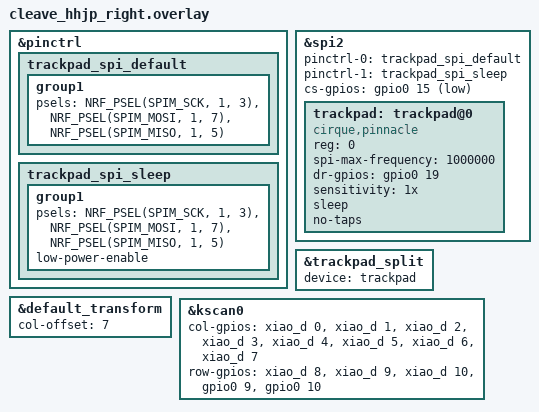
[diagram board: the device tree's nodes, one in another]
/*
 * Copyright (c) 2025
 * SPDX-License-Identifier: MIT
 */

#include "cleave_hhjp.dtsi"
#include "cleave_hhjp_trackpad.dtsi"

&pinctrl {
	trackpad_spi_default: trackpad_spi_default {
		group1 {
			/* Yellow: D17/SCK, blue: D19/SI, green: D18/SO. */
			psels = <NRF_PSEL(SPIM_SCK, 1, 3)>,
				<NRF_PSEL(SPIM_MOSI, 1, 7)>,
				<NRF_PSEL(SPIM_MISO, 1, 5)>;
		};
	};

	trackpad_spi_sleep: trackpad_spi_sleep {
		group1 {
			psels = <NRF_PSEL(SPIM_SCK, 1, 3)>,
				<NRF_PSEL(SPIM_MOSI, 1, 7)>,
				<NRF_PSEL(SPIM_MISO, 1, 5)>;
			low-power-enable;
		};
	};
};

&spi2 {
	status = "okay";
	pinctrl-0 = <&trackpad_spi_default>;
	pinctrl-1 = <&trackpad_spi_sleep>;
	pinctrl-names = "default", "sleep";
	cs-gpios = <&gpio0 15 GPIO_ACTIVE_LOW>; /* Brown: D11/SS. */

	trackpad: trackpad@0 {
		compatible = "cirque,pinnacle";
		reg = <0>;
		spi-max-frequency = <1000000>;
		dr-gpios = <&gpio0 19 GPIO_ACTIVE_HIGH>; /* Orange: D12/DR. */
		sensitivity = "1x";
		sleep;
		no-taps;
	};
};

&trackpad_split {
	device = <&trackpad>;
};

&default_transform {
	col-offset = <7>;
};

&kscan0 {
	col-gpios
		= <&xiao_d 0 GPIO_ACTIVE_HIGH>
		, <&xiao_d 1 GPIO_ACTIVE_HIGH>
		, <&xiao_d 2 GPIO_ACTIVE_HIGH>
		, <&xiao_d 3 GPIO_ACTIVE_HIGH>
		, <&xiao_d 4 GPIO_ACTIVE_HIGH>
		, <&xiao_d 5 GPIO_ACTIVE_HIGH>
		, <&xiao_d 6 GPIO_ACTIVE_HIGH>
		, <&xiao_d 7 GPIO_ACTIVE_HIGH>
		;

	row-gpios
		= <&xiao_d 8 (GPIO_ACTIVE_HIGH | GPIO_PULL_DOWN)>
		, <&xiao_d 9 (GPIO_ACTIVE_HIGH | GPIO_PULL_DOWN)>
		, <&xiao_d 10 (GPIO_ACTIVE_HIGH | GPIO_PULL_DOWN)>
		, <&gpio0 9 (GPIO_ACTIVE_HIGH | GPIO_PULL_DOWN)>   // NFC1 (P0.09)
		, <&gpio0 10 (GPIO_ACTIVE_HIGH | GPIO_PULL_DOWN)>  // NFC2 (P0.10)
		;
};
